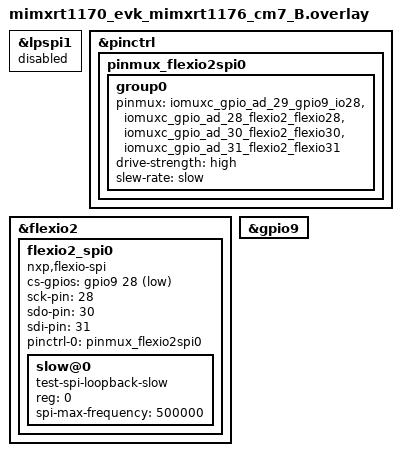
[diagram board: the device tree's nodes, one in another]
/*
 * Copyright 2023 NXP
 *
 * SPDX-License-Identifier: Apache-2.0
 */


/*
// LPSPI CONFIGURATIONS
 &lpspi1 {
	slow@0 {
		compatible = "test-spi-loopback-slow";
		reg = <0>;
		spi-max-frequency = <500000>;
	};
};

*/


&lpspi1 {
	status = "disabled";
};


&pinctrl {
	pinmux_flexio2spi0: pinmux_flexio2spi0 {
		group0 {
			pinmux =
				<&iomuxc_gpio_ad_29_gpio9_io28>, /* cs GPIO_AD_29 */				// AD29 PIN CONTROLLED AS GPIO, ENABLING THIS LINE DOESN'T SEEM CHANGE THE BEHAVIOR
				<&iomuxc_gpio_ad_28_flexio2_flexio28>, /* sck GPIO_AD_28 */
				<&iomuxc_gpio_ad_30_flexio2_flexio30>, /* sdo GPIO_AD_30 */
				<&iomuxc_gpio_ad_31_flexio2_flexio31>; /* sdi GPIO_AD_31 */
			drive-strength = "high";
			slew-rate = "slow";
		};
	};
};


&flexio2 {
	status = "okay";
	flexio2_spi0: flexio2_spi0 {
		compatible = "nxp,flexio-spi";
		status = "okay";
		#address-cells = <1>;
		#size-cells = <0>;
		cs-gpios = <&gpio9 28 GPIO_ACTIVE_LOW>;		//AD29 IS GPIO IO 28
		sck-pin = <28>;
		sdo-pin = <30>;
		sdi-pin = <31>;
		pinctrl-0 = <&pinmux_flexio2spi0>;
		pinctrl-names = "default";
		slow@0 {
			status = "okay";
			compatible = "test-spi-loopback-slow";
			reg = <0>;
			spi-max-frequency = <500000>;
		};
	};

};


&gpio9 {
	status = "okay";
};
